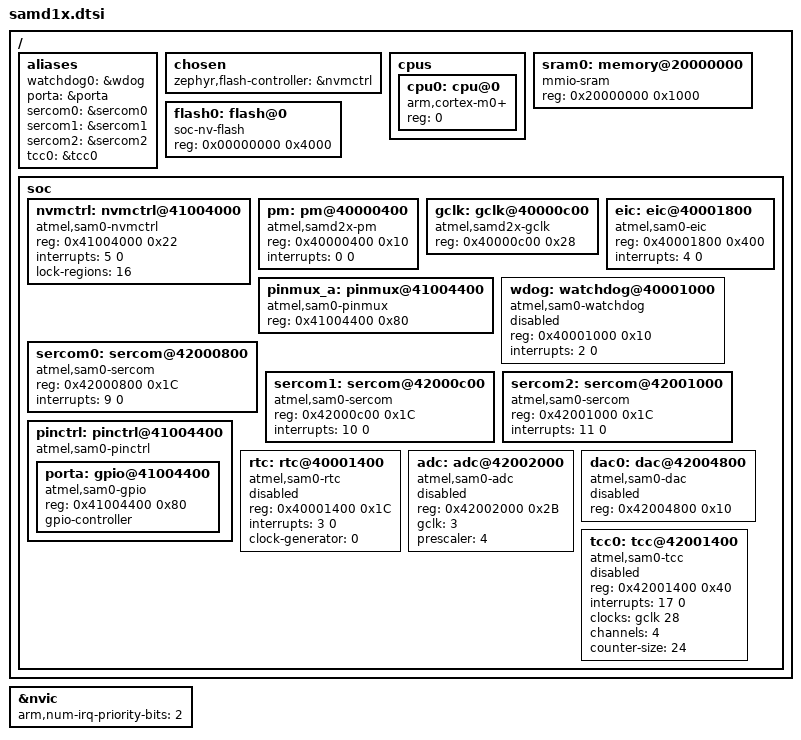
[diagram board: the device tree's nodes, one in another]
/*
 * Copyright (c) 2017 Google LLC.
 *
 * SPDX-License-Identifier: Apache-2.0
 */

 #include <mem.h>
 #include <arm/armv6-m.dtsi>
 #include <zephyr/dt-bindings/adc/adc.h>
 #include <zephyr/dt-bindings/gpio/gpio.h>
 #include <zephyr/dt-bindings/i2c/i2c.h>
 #include <zephyr/dt-bindings/pwm/pwm.h>
 
 / {
    aliases {
		watchdog0 = &wdog;
        porta = &porta;
        sercom0 = &sercom0;
        sercom1 = &sercom1;
        sercom2 = &sercom2;
        tcc0 = &tcc0;
	};

	chosen {
		zephyr,flash-controller = &nvmctrl;
	};

	cpus {
        #address-cells = <1>;
        #size-cells = <0>;

        cpu0: cpu@0 {
            device_type = "cpu";
            compatible = "arm,cortex-m0+";
            reg = <0>;
        };
    };
 
    sram0: memory@20000000 {
		compatible = "mmio-sram";
        reg = <0x20000000 0x1000>; /* 4KB SRAM */
    };

    flash0: flash@0 {
        compatible = "soc-nv-flash";
        reg = <0x00000000 0x4000>; /* 16KB Flash */
    };
 
    //  id: device_id@80a00c {
    //      compatible = "atmel,sam0-id";
    //      reg =	<0x0080A00C 0x4>,
    //          <0x0080A040 0x4>,
    //          <0x0080A044 0x4>,
    //          <0x0080A048 0x4>;
    //  };
 
     soc {
        #address-cells = <1>;
        #size-cells = <1>;

        nvmctrl: nvmctrl@41004000 {
            compatible = "atmel,sam0-nvmctrl";
            reg = <0x41004000 0x22>;
            interrupts = <5 0>;
            lock-regions = <16>;
        };
 
        pm: pm@40000400 {
            compatible = "atmel,samd2x-pm";
            reg = <0x40000400 0x10>;
            interrupts = <0 0>;
			#clock-cells = <2>;
        };
 
        gclk: gclk@40000c00 {
             compatible = "atmel,samd2x-gclk";
             reg = <0x40000c00 0x28>;
             #clock-cells = <1>;
        };
 
        eic: eic@40001800{
             compatible = "atmel,sam0-eic";
             reg = <0x40001800 0x400>;
             interrupts = <4 0>;
             status = "okay";
         };
 
        pinmux_a: pinmux@41004400 {
             compatible = "atmel,sam0-pinmux";
             reg = <0x41004400 0x80>;
             status = "okay";
         };
 
         wdog: watchdog@40001000 {
             compatible = "atmel,sam0-watchdog";
             reg = <0x40001000 0x10>;
             interrupts = <2 0>;
             status = "disabled";
         };
 
         sercom0: sercom@42000800 {
             compatible = "atmel,sam0-sercom";
             reg = <0x42000800 0x1C>;
             interrupts = <9 0>;
         };
 
         sercom1: sercom@42000c00 {
             compatible = "atmel,sam0-sercom";
             reg = <0x42000c00 0x1C>;
             interrupts = <10 0>;
         };
 
         sercom2: sercom@42001000 {
             compatible = "atmel,sam0-sercom";
             reg = <0x42001000 0x1C>;
             interrupts = <11 0>;
         };
 
         pinctrl: pinctrl@41004400 {
             compatible = "atmel,sam0-pinctrl";
             #address-cells = <1>;
             #size-cells = <1>;
             ranges = <0x41004400 0x41004400 0x80>;
             porta: gpio@41004400 {
                 compatible = "atmel,sam0-gpio";
                 reg = <0x41004400 0x80>;
                 gpio-controller;
                 #gpio-cells = <2>;
                 #atmel,pin-cells = <2>;
 
             };
         };
 
         rtc: rtc@40001400 {
             compatible = "atmel,sam0-rtc";
             reg = <0x40001400 0x1C>;
             interrupts = <3 0>;
             clock-generator = <0>;
             status = "disabled";
         };
 
         adc: adc@42002000 {
             compatible = "atmel,sam0-adc";
             reg = <0x42002000 0x2B>;
             status = "disabled";
             /*
              * 2.1 MHz max, so clock it with the
              * 8 MHz GCLK / 4 = 2 MHz
              */
             gclk = <3>;
             prescaler = <4>;
             #io-channel-cells = <1>;
         };
 
         dac0: dac@42004800 {
             compatible = "atmel,sam0-dac";
             status = "disabled";
             reg = <0x42004800 0x10>;
             #io-channel-cells = <0>;
             status = "disabled";
         };

         tcc0: tcc@42001400 {
			compatible = "atmel,sam0-tcc";
			reg = <0x42001400 0x40>;
			interrupts = <17 0>;
			clocks = <&gclk 28>;
			clock-names = "GCLK";

			channels = <4>;
			counter-size = <24>;
            status = "disabled";
		};
     };
 };
 
 &nvic {
    arm,num-irq-priority-bits = <2>;
};
 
